# STM32F101 register map
File version: 1.1
CPU: CM3 r1p1, little endian, no MPU, no FPU, 4 interrupt priority bits
Registers are 32-bit, read-write, reset 0x0 unless marked. A register's access mark holds for its fields unless they carry their own. Offsets are from the block's base; [hi:lo] are bit positions; {n}, {i} and the like mark numbered series; <NAME> marks a mode.

## DBGMCU — Debug support
Base 0xE0042000
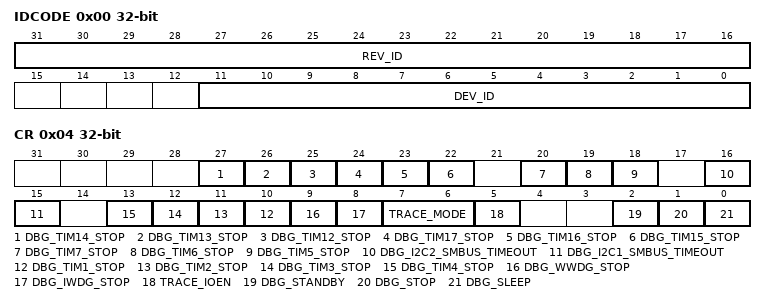
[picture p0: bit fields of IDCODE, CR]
0x00 IDCODE ro — DBGMCU_IDCODE
  [31:16] REV_ID, [11:0] DEV_ID
0x04 CR — DBGMCU_CR
  [27] DBG_TIM14_STOP — TIM14 counter stopped when core is halted
  [26] DBG_TIM13_STOP — TIM13 counter stopped when core is halted
  [25] DBG_TIM12_STOP — TIM12 counter stopped when core is halted
  [24] DBG_TIM17_STOP — TIM17 counter stopped when core is halted
  [23] DBG_TIM16_STOP — TIM16 counter stopped when core is halted
  [22] DBG_TIM15_STOP — TIM15 counter stopped when core is halted
  [20] DBG_TIM7_STOP
  [19] DBG_TIM6_STOP
  [18] DBG_TIM5_STOP
  [16] DBG_I2C2_SMBUS_TIMEOUT
  [15] DBG_I2C1_SMBUS_TIMEOUT
  [n+9] DBG_TIM{n}_STOP (n=1..4)
  [9] DBG_WWDG_STOP
  [8] DBG_IWDG_STOP
  [7:6] TRACE_MODE
  [5] TRACE_IOEN
  [2] DBG_STANDBY
  [1] DBG_STOP
  [0] DBG_SLEEP

## CRC — CRC calculation unit
Base 0x40023000
0x00 DR reset 0xFFFFFFFF — Data register
  [31:0] DR — Data Register
0x04 IDR — Independent Data register
  [7:0] IDR
0x08 CR wo — Control register
  [0] RESET — Reset bit
    1=Resets the CRC calculation unit and sets the data register to 0xFFFF FFFF

## FLASH
Base 0x40022000
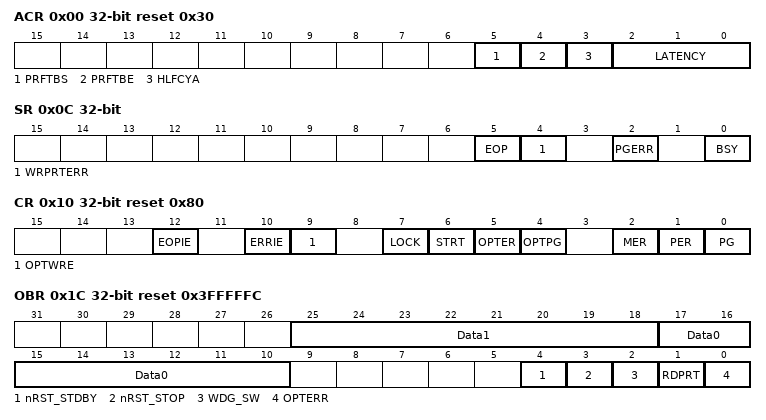
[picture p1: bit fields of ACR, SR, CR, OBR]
0x00 ACR access per field reset 0x30 — Flash access control register
  [5] PRFTBS ro — Prefetch buffer status
  [4] PRFTBE rw — Prefetch buffer enable
  [3] HLFCYA rw — Flash half cycle access enable
  [2:0] LATENCY rw
    0=WS0 (Zero wait state, if 0 < SYSCLK≤ 24 MHz); 1=WS1 (One wait state, if 24 MHz < SYSCLK ≤ 48 MHz); 2=WS2 (Two wait states, if 48 MHz < SYSCLK ≤ 72 MHz)
0x04 KEYR wo — Flash key register
  [31:0] KEY — FPEC key
0x08 OPTKEYR wo — Flash option key register
  [31:0] OPTKEY — Option byte key
0x0C SR access per field — Status register
  [5] EOP rw — End of operation
  [4] WRPRTERR rw — Write protection error
  [2] PGERR rw — Programming error
  [0] BSY ro — Busy
0x10 CR reset 0x80 — Control register
  [12] EOPIE — End of operation interrupt enable
  [10] ERRIE — Error interrupt enable
  [9] OPTWRE — Option bytes write enable
  [7] LOCK
  [6] STRT — Start
  [5] OPTER — Option byte erase
  [4] OPTPG — Option byte programming
  [2] MER — Mass Erase
  [1] PER — Page Erase
  [0] PG — Programming
0x14 AR wo — Flash address register
  [31:0] FAR — Flash Address
0x1C OBR ro reset 0x3FFFFFC — Option byte register
  [25:18] Data1
  [17:10] Data0
  [4] nRST_STDBY
  [3] nRST_STOP
  [2] WDG_SW
  [1] RDPRT — Read protection
  [0] OPTERR — Option byte error
0x20 WRPR ro reset 0xFFFFFFFF — Write protection register
  [31:0] WRP — Write protect

## BKP — Backup registers
Base 0x40006C04
0x00 DR{i} (i=1..10; step 0x4) — Backup data register (BKP_DR)
  [15:0] D — Backup data
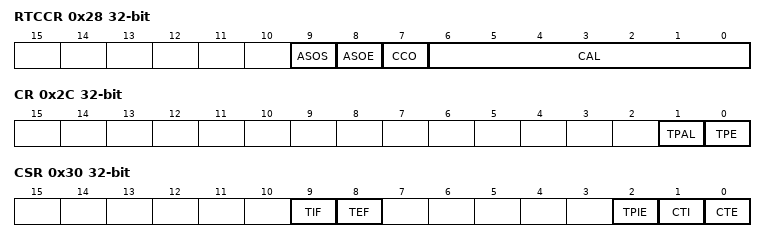
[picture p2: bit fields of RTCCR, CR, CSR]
0x28 RTCCR — RTC clock calibration register (BKP_RTCCR)
  [9] ASOS — Alarm or second output selection
    0=Alarm (RTC Alarm pulse output selected); 1=Second (RTC Second pulse output selected)
  [8] ASOE — Alarm or second output enable
    0=Disabled; 1=Enabled (Setting this bit outputs either the RTC Alarm pulse signal or the Second pulse signal on the TAMPER pin depending on the ASOS bit)
  [7] CCO — Calibration Clock Output
  [6:0] CAL range 0..121 — Calibration value
0x2C CR — Backup control register (BKP_CR)
  [1] TPAL — Tamper pin active level
    0=High (A high level on the TAMPER pin resets all data backup registers (if TPE bit is set)); 1=Low (A low level on the TAMPER pin resets all data backup registers (if TPE bit is set))
  [0] TPE — Tamper pin enable
    0=General (The TAMPER pin is free for general purpose I/O); 1=Alternate (Tamper alternate I/O function is activated)
0x30 CSR access per field — BKP_CSR control/status register (BKP_CSR)
  [9] TIF ro — Tamper Interrupt Flag
  [8] TEF ro — Tamper Event Flag
  [2] TPIE rw — Tamper Pin interrupt enable
    0=Disabled (Tamper interrupt disabled); 1=Enabled (Tamper interrupt enabled (the TPE bit must also be set in the BKP_CR register)
  [1] CTI wo — Clear Tamper Interrupt
    1=Clear the Tamper interrupt and the TIF Tamper interrupt flag
  [0] CTE wo — Clear Tamper event
    1=Reset the TEF Tamper event flag (and the Tamper detector)
{0x10+4i} BKP_DR{i} (i=11..42) — Backup data register (BKP_DR)
  [15:0] D — Backup data
